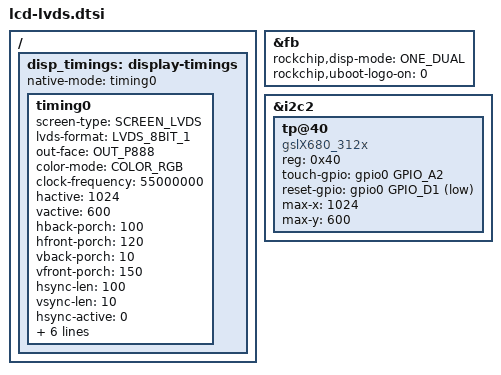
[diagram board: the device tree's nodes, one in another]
&fb {
        rockchip,disp-mode = <ONE_DUAL>;
        rockchip,uboot-logo-on = <0>;
};

&i2c2 {
        status = "okay";
        tp@40 {
                compatible = "gslX680_312x";
                reg = <0x40>;
                touch-gpio = <&gpio0 GPIO_A2 IRQ_TYPE_LEVEL_LOW>;       /* TP_INT == GPIO1_B0 */
                reset-gpio = <&gpio0 GPIO_D1 GPIO_ACTIVE_LOW>;          /* TP_RST == GPIO0_D1 */
                max-x = <1024>;
                max-y = <600>;
                status = "okay";
        };
};
/ {

        disp_timings: display-timings {
                native-mode = <&timing0>;

                timing0: timing0 {
                                screen-type = <SCREEN_LVDS>;
                                lvds-format = <LVDS_8BIT_1>;
                                out-face    = <OUT_P888>;
                                color-mode = <COLOR_RGB>;
                                clock-frequency = <55000000>;
                                hactive = <1024>;
                                vactive = <600>;
                                hback-porch = <100>;
                                hfront-porch = <120>;
                                vback-porch = <10>;
                                vfront-porch = <150>;
                                hsync-len = <100>;
                                vsync-len = <10>;
                                hsync-active = <0>;
                                vsync-active = <0>;
                                de-active = <0>;
                                pixelclk-active = <0>;
                                swap-rb = <1>;
                                swap-rg = <0>;
                                swap-gb = <0>;
                    };
        };
};

